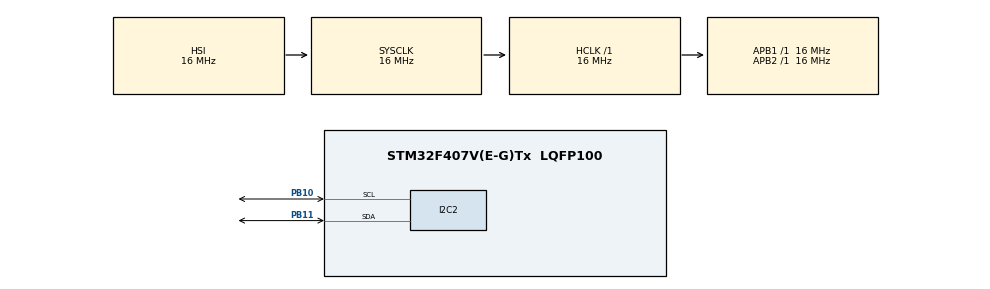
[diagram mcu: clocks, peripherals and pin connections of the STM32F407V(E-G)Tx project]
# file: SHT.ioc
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Mcu.Family=STM32F4
Mcu.Name=STM32F407V(E-G)Tx
Mcu.Package=LQFP100
NVIC.PriorityGroup=NVIC_PRIORITYGROUP_4
PB10.Mode=I2C
PB10.Signal=I2C2_SCL
PB11.Mode=I2C
PB11.Signal=I2C2_SDA
ProjectManager.HeapSize=0x200
ProjectManager.StackSize=0x400
ProjectManager.TargetToolchain=STM32CubeIDE
RCC.AHBFreq_Value=16000000
RCC.APB1Freq_Value=16000000
RCC.APB2Freq_Value=16000000
RCC.CortexFreq_Value=16000000
RCC.HSE_VALUE=25000000
RCC.HSI_VALUE=16000000
RCC.LSE_VALUE=32768
RCC.SYSCLKFreq_VALUE=16000000
RCC.VCOOutputFreq_Value=192000000
board=custom

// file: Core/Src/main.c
/* USER CODE BEGIN Header */
/**
  ******************************************************************************
  * @file           : main.c
  * @brief          : Main program body
  ******************************************************************************
  * @attention
  *
  * Copyright (c) 2024 STMicroelectronics.
  * All rights reserved.
  *
  * This software is licensed under terms that can be found in the LICENSE file
  * in the root directory of this software component.
  * If no LICENSE file comes with this software, it is provided AS-IS.
  *
  ******************************************************************************
  */
/* USER CODE END Header */
#include "main.h"
#include "sensor_data.h"
/* USER CODE BEGIN Includes */

// Define necessary constants for SHT3X sensor

#define SHT30_I2C_ADDR                      0x44
#define I2C_WRITE 0x00
#define I2C_READ  0x01

#define SHT3X_CMD_READ_STATUS               0xF32D
#define SHT3X_CMD_CLEAR_STATUS              0x3041
#define SHT3X_CMD_SOFT_RESET                0x30A2

#define MAX_RECV_DATA_SIZE 3
#define CMD_MEASURE_HIGHREP_STRETCH 0x2C06 // Command for high repeatability measurement with clock stretching
#define CMD_MEASURE_HUMIDITY 0x2400 // Command for high repeatability measurement without clock stretching

/* USER CODE END Includes */

I2C_HandleTypeDef hi2c2;

void SystemClock_Config(void);
static void MX_GPIO_Init(void);
static void MX_I2C2_Init(void);

int main(void)
{
  /* USER CODE BEGIN 1 */
	// Define a union for temperature and humidity data

SensorData sensorData;  // Example variable declaration

uint32_t tempData;
    uint32_t humiData;
	    float temperature;
	    float humidity;
	    uint16_t statusreg;
	    uint8_t data[6];

	    uint32_t startAddress = 0x0800C000;
  unsigned char result;
    extern I2C_HandleTypeDef hi2c1;
int i;
    static uint32_t lastTime = 0;
       // uint32_t currentTime = HAL_GetTick();
  /* USER CODE END 1 */

  /* MCU Configuration--------------------------------------------------------*/

  /* Reset of all peripherals, Initializes the Flash interface and the Systick. */
  HAL_Init();

  /* USER CODE BEGIN Init */
  SHT_init(&hi2c2);
  /* USER CODE END Init */

  /* Configure the system clock */
  SystemClock_Config();
  HAL_Delay(10000);

  /* Initialize all configured peripherals */
  MX_GPIO_Init();
  MX_I2C2_Init();
  /* USER CODE BEGIN 2 */

 // ReadAllValuesFromFlash(startAddress, tempData, humiData );
  Flash_Erase(startAddress);
ReadAllValuesFromFlash(startAddress, tempData, humiData);
  /* USER CODE END 2 */

  /* Infinite loop */
  /* USER CODE BEGIN WHILE */
  while (1)
  {

	 SHT_write(&hi2c2);
 SHT_read(&hi2c2, &temperature, &humidity);
  SHT_writestatus(&hi2c2);
  read_status_register(&statusreg,&hi2c2);
heater_on(&hi2c2);
  sensorData.fields.temp_data = (data[0] << 8) | (data[1] & 0xFF);
    sensorData.fields.temp_crc = data[2];
     sensorData.fields.temp_crc_expected = calculate_crc8(data, 2);
     sensorData.fields.humi_data = (data[3] << 8) | (data[4] & 0xFF);
     sensorData.fields.humi_crc = data[5];
     sensorData.fields.humi_crc_expected = calculate_crc8(data + 3, 2);
     WriteValuesToFlash(startAddress,sensorData.values[0],sensorData.values[1]);
     startAddress += 8; // Move to the next address (4 bytes for temp + 4 bytes for humidity)
     HAL_Delay(5000);
    /* USER CODE END WHILE */

  }
}

void SystemClock_Config(void)
{
  RCC_OscInitTypeDef RCC_OscInitStruct = {0};
  RCC_ClkInitTypeDef RCC_ClkInitStruct = {0};

  /** Configure the main internal regulator output voltage
  */
  __HAL_RCC_PWR_CLK_ENABLE();
  __HAL_PWR_VOLTAGESCALING_CONFIG(PWR_REGULATOR_VOLTAGE_SCALE1);

  /** Initializes the RCC Oscillators according to the specified parameters
  * in the RCC_OscInitTypeDef structure.
  */
  RCC_OscInitStruct.OscillatorType = RCC_OSCILLATORTYPE_HSI;
  RCC_OscInitStruct.HSIState = RCC_HSI_ON;
  RCC_OscInitStruct.HSICalibrationValue = RCC_HSICALIBRATION_DEFAULT;
  RCC_OscInitStruct.PLL.PLLState = RCC_PLL_NONE;
  if (HAL_RCC_OscConfig(&RCC_OscInitStruct) != HAL_OK)
  {
    Error_Handler();
  }

  /** Initializes the CPU, AHB and APB buses clocks
  */
  RCC_ClkInitStruct.ClockType = RCC_CLOCKTYPE_HCLK|RCC_CLOCKTYPE_SYSCLK
                              |RCC_CLOCKTYPE_PCLK1|RCC_CLOCKTYPE_PCLK2;
  RCC_ClkInitStruct.SYSCLKSource = RCC_SYSCLKSOURCE_HSI;
  RCC_ClkInitStruct.AHBCLKDivider = RCC_SYSCLK_DIV1;
  RCC_ClkInitStruct.APB1CLKDivider = RCC_HCLK_DIV1;
  RCC_ClkInitStruct.APB2CLKDivider = RCC_HCLK_DIV1;

  if (HAL_RCC_ClockConfig(&RCC_ClkInitStruct, FLASH_LATENCY_0) != HAL_OK)
  {
    Error_Handler();
  }
}

static void MX_I2C2_Init(void)
{

  hi2c2.Instance = I2C2;
  hi2c2.Init.ClockSpeed = 100000;
  hi2c2.Init.DutyCycle = I2C_DUTYCYCLE_2;
  hi2c2.Init.OwnAddress1 = 0;
  hi2c2.Init.AddressingMode = I2C_ADDRESSINGMODE_7BIT;
  hi2c2.Init.DualAddressMode = I2C_DUALADDRESS_DISABLE;
  hi2c2.Init.OwnAddress2 = 0;
  hi2c2.Init.GeneralCallMode = I2C_GENERALCALL_DISABLE;
  hi2c2.Init.NoStretchMode = I2C_NOSTRETCH_DISABLE;
  if (HAL_I2C_Init(&hi2c2) != HAL_OK)
  {
    Error_Handler();
  }

}

static void MX_GPIO_Init(void)
{

  /* GPIO Ports Clock Enable */
  __HAL_RCC_GPIOB_CLK_ENABLE();

}

/* USER CODE BEGIN 4 */

void SHT_init(I2C_HandleTypeDef *hi2c) {
    MX_I2C2_Init();  // Initialize I2C as per your current implementation
}

void Error_Handler(void)
{
  /* USER CODE BEGIN Error_Handler_Debug */
  /* User can add his own implementation to report the HAL error return state */
  __disable_irq();
  while (1)
  {
  }
  /* USER CODE END Error_Handler_Debug */
}

/* USER CODE END 4 */
